AUTOSAR XML (schema 4-2-1)
package /ComponentTypes
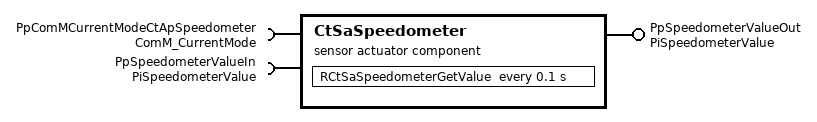
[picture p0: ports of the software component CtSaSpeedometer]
  sensor actuator sw component type CtSaSpeedometer
    provide port PpSpeedometerValueOut: nonqueued-sender-com-spec{data-element=DeSpeedometerValue, init-value=0}, provided-interface=PiSpeedometerValue
    require port PpComMCurrentModeCtApSpeedometer: required-interface=ComM_CurrentMode
    require port PpSpeedometerValueIn: nonqueued-receiver-com-spec{data-element=DeSpeedometerValue, filter=data-filter-type=ALWAYS, init-value=constant-reference=CInitSpeed}, required-interface=PiSpeedometerValue
    behavior CtSaSpeedometer_InternalBehavior
      timing event TMT_RCtSaSpeedometerGetValue: start-on-event=RCtSaSpeedometerGetValue, period=0.1
      runnable RCtSaSpeedometerGetValue
        data-receive-point-by-arguments:
          access REC_PpSpeedometerValueIn_DeSpeedometerValue: accessed-variable=PpSpeedometerValueIn.DeSpeedometerValue
        data-send-points:
          access SEND_PpSpeedometerValueOut_DeSpeedometerValue: accessed-variable=PpSpeedometerValueOut.DeSpeedometerValue
  swc implementation CtSaSpeedometer_Implementation: behavior=CtSaSpeedometer_InternalBehavior
    code-descriptors:
      code Default: artifact-descriptors=autosar-engineering-object={short-label=Default, category=SWSRC}
